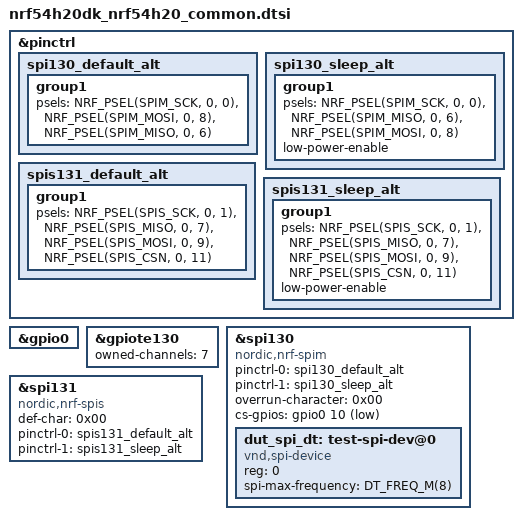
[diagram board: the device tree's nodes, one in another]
/*
 * Copyright (c) 2024 Nordic Semiconductor
 *
 * SPDX-License-Identifier: Apache-2.0
 */

&pinctrl {
	spi130_default_alt: spi130_default_alt {
		group1 {
			psels = <NRF_PSEL(SPIM_SCK, 0, 0)>,
				<NRF_PSEL(SPIM_MOSI, 0, 8)>,
				<NRF_PSEL(SPIM_MISO, 0, 6)>;
		};
	};

	spi130_sleep_alt: spi130_sleep_alt {
		group1 {
			psels = <NRF_PSEL(SPIM_SCK, 0, 0)>,
				<NRF_PSEL(SPIM_MISO, 0, 6)>,
				<NRF_PSEL(SPIM_MOSI, 0, 8)>;
			low-power-enable;
		};
	};

	spis131_default_alt: spis131_default_alt {
		group1 {
			psels = <NRF_PSEL(SPIS_SCK, 0, 1)>,
				<NRF_PSEL(SPIS_MISO, 0, 7)>,
				<NRF_PSEL(SPIS_MOSI, 0, 9)>,
				<NRF_PSEL(SPIS_CSN, 0, 11)>;
		};
	};

	spis131_sleep_alt: spis131_sleep_alt {
		group1 {
			psels = <NRF_PSEL(SPIS_SCK, 0, 1)>,
				<NRF_PSEL(SPIS_MISO, 0, 7)>,
				<NRF_PSEL(SPIS_MOSI, 0, 9)>,
				<NRF_PSEL(SPIS_CSN, 0, 11)>;
			low-power-enable;
		};
	};

};

&gpio0 {
	status = "okay";
};

&gpiote130 {
	status = "okay";
	owned-channels = <7>;
};

&spi130 {
	compatible = "nordic,nrf-spim";
	status = "okay";
	pinctrl-0 = <&spi130_default_alt>;
	pinctrl-1 = <&spi130_sleep_alt>;
	pinctrl-names = "default", "sleep";
	overrun-character = <0x00>;
	cs-gpios = <&gpio0 10 GPIO_ACTIVE_LOW>;
	dut_spi_dt: test-spi-dev@0 {
		compatible = "vnd,spi-device";
		reg = <0>;
		spi-max-frequency = <DT_FREQ_M(8)>;
	};
};

dut_spis: &spi131 {
	compatible = "nordic,nrf-spis";
	status = "okay";
	def-char = <0x00>;
	pinctrl-0 = <&spis131_default_alt>;
	pinctrl-1 = <&spis131_sleep_alt>;
	pinctrl-names = "default", "sleep";
	/delete-property/rx-delay-supported;
	/delete-property/rx-delay;
};
